# MCXN947_cm33_core0 register map
Vendor: nxp.com; File version: 1.0
CPU: CM33 r2p0, little endian, MPU, FPU, VTOR, 3 interrupt priority bits
Registers are 32-bit, read-write, reset 0x0 unless marked. A register's access mark holds for its fields unless they carry their own. Offsets are from the block's base; [hi:lo] are bit positions; lines under a group give offsets from that group; {n}, {i} and the like mark numbered series; 'fields as' and 'values as' point back to an identical list.

## CAN0 — CAN
Base 0x400D4000
Same registers: CAN1 0x400D8000
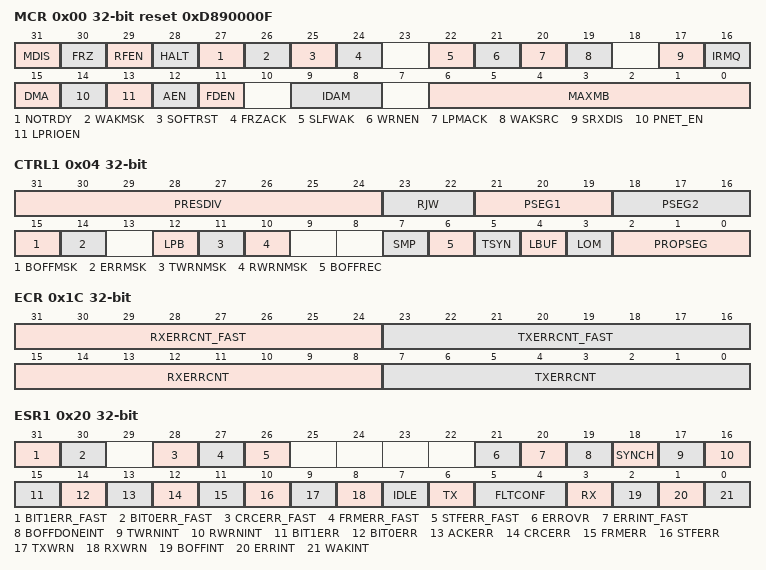
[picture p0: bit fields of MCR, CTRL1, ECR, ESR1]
0x00 MCR reset 0xD890000F — Module Configuration Register
  [31] MDIS — Module Disable
    0=flexcan_enabled (Enable the FlexCAN module.); 1=flexcan_disabled (Disable the FlexCAN module.)
  [30] FRZ — Freeze Enable
    0=freeze_mode_disabled (Not enabled to enter Freeze mode.); 1=freeze_mode_enabled (Enabled to enter Freeze mode.)
  [29] RFEN — Legacy Rx FIFO Enable
    0=id1 (Legacy Rx FIFO not enabled.); 1=id3 (Legacy Rx FIFO enabled.)
  [28] HALT — Halt FlexCAN
    0=HALT_disable (No Freeze mode request.); 1=HALT_enable (Enters Freeze mode if the FRZ bit is asserted.)
  [27] NOTRDY ro — FlexCAN Not Ready
    0=id1 (FlexCAN module is either in Normal mode, Listen-Only mode, or Loop-Back mode.); 1=id4 (FlexCAN module is either in Disable mode, Stop mode, or Freeze mode.)
  [26] WAKMSK — Wake Up Interrupt Mask
    0=wakeup_interrupt_disabled (Wake Up interrupt is disabled.); 1=wakeup_interrupt_enabled (Wake Up interrupt is enabled.)
  [25] SOFTRST — Soft Reset
    0=SOFTRST_no_reset_request (No reset request.); 1=SOFTRST_reset_registers (Resets the registers affected by soft reset.)
  [24] FRZACK ro — Freeze Mode Acknowledge
    0=freeze_mode_no (FlexCAN not in Freeze mode, prescaler running.); 1=freeze_mode_yes (FlexCAN in Freeze mode, prescaler stopped.)
  [22] SLFWAK — Self Wake Up
    0=self_wakeup_disabled (FlexCAN Self Wake Up feature is disabled.); 1=self_wakeup_enabled (FlexCAN Self Wake Up feature is enabled.)
  [21] WRNEN — Warning Interrupt Enable
    0=TWRNINT_RWRNINT_inactive (TWRNINT and RWRNINT bits are zero, independent of the values in the error counters.); 1=TWRNINT_RWRNINT_active (TWRNINT and RWRNINT bits are set when the respective error counter transitions from less than 96 to greater than or equal to 96.)
  [20] LPMACK ro — Low-Power Mode Acknowledge
    0=low_power_no (FlexCAN is not in a low-power mode.); 1=low_power_yes (FlexCAN is in a low-power mode.)
  [19] WAKSRC — Wake Up Source
    0=unfiltered_rx_input (FlexCAN uses the unfiltered Rx input to detect recessive to dominant edges on the CAN bus.); 1=filtered_rx_input (FlexCAN uses the filtered Rx input to detect recessive to dominant edges on the CAN bus.)
  [17] SRXDIS — Self Reception Disable
    0=self_reception_enabled; 1=self_reception_disabled
  [16] IRMQ — Individual Rx Masking And Queue Enable
    0=individual_rx_masking_disabled (Individual Rx masking and queue feature are disabled. For backward compatibility with legacy applications, the reading of C/S word locks the MB even if it is EMPTY.); 1=individual_rx_masking_enabled (Individual Rx masking and queue feature are enabled.)
  [15] DMA — DMA Enable
    0=id1 (DMA feature for Legacy RX FIFO or Enhanced Rx FIFO disabled.); 1=id3 (DMA feature for Legacy RX FIFO or Enhanced Rx FIFO enabled.)
  [14] PNET_EN — Pretended Networking Enable
    0=PN_disabled (Pretended Networking mode is disabled.); 1=PN_enabled (Pretended Networking mode is enabled.)
  [13] LPRIOEN — Local Priority Enable
    0=local_priority_disabled; 1=local_priority_enabled
  [12] AEN — Abort Enable
    0=abort_disabled; 1=abort_enabled
  [11] FDEN — CAN FD operation enable
    0=CAN_FD_disabled (CAN FD is disabled. FlexCAN is able to receive and transmit messages in CAN 2.0 format.); 1=CAN_FD_enabled (CAN FD is enabled. FlexCAN is able to receive and transmit messages in both CAN FD and CAN 2.0 formats.)
  [9:8] IDAM — ID Acceptance Mode
    0=one_full_ID (Format A: One full ID (standard and extended) per ID filter table element.); 1=two_full_ID (Format B: Two full standard IDs or two partial 14-bit (standard and extended) IDs per ID filter table element.); 2=four_partial_ID (Format C: Four partial 8-bit standard IDs per ID filter table element.); 3=all_frames_rejected (Format D: All frames rejected.)
  [6:0] MAXMB — Number Of The Last Message Buffer
0x04 CTRL1 — Control 1 Register
  [31:24] PRESDIV — Prescaler Division Factor
  [23:22] RJW — Resync Jump Width
  [21:19] PSEG1 — Phase Segment 1
  [18:16] PSEG2 — Phase Segment 2
  [15] BOFFMSK — Bus Off Interrupt Mask
    0=bus_off_int_disabled (Bus Off interrupt disabled.); 1=bus_off_int_enabled (Bus Off interrupt enabled.)
  [14] ERRMSK — Error Interrupt Mask
    0=error_int_disabled (Error interrupt disabled.); 1=error_int_enabled (Error interrupt enabled.)
  [12] LPB — Loop Back Mode
    0=loopback_disabled; 1=loopback_enabled
  [11] TWRNMSK — Tx Warning Interrupt Mask
    0=tx_warning_int_disabled (Tx Warning interrupt disabled.); 1=tx_warning_int_enabled (Tx Warning interrupt enabled.)
  [10] RWRNMSK — Rx Warning Interrupt Mask
    0=rx_warning_int_disabled (Rx Warning interrupt disabled.); 1=rx_warning_int_enabled (Rx Warning interrupt enabled.)
  [7] SMP — CAN Bit Sampling
    0=one_sample (Just one sample is used to determine the bit value.); 1=Three samples are used to determine the value of the received bit: the regular one (sample point) and two preceding samples; a majority rule is used
  [6] BOFFREC — Bus Off Recovery
    0=auto_recover_enabled (Automatic recovering from Bus Off state enabled.); 1=auto_recover_disabled (Automatic recovering from Bus Off state disabled.)
  [5] TSYN — Timer Sync
    0=timer_sync_disabled (Timer sync feature disabled); 1=timer_sync_enabled (Timer sync feature enabled)
  [4] LBUF — Lowest Buffer Transmitted First
    0=highest_buffer_first (Buffer with highest priority is transmitted first.); 1=lowest_buffer_first (Lowest number buffer is transmitted first.)
  [3] LOM — Listen-Only Mode
    0=listen_only_mode_disabled (Listen-Only mode is deactivated.); 1=listen_only_mode_enabled (FlexCAN module operates in Listen-Only mode.)
  [2:0] PROPSEG — Propagation Segment
0x08 TIMER — Free Running Timer
  [15:0] TIMER — Timer Value
0x10 RXMGMASK reset not defined — Rx Mailboxes Global Mask Register
  [31:0] MG — Rx Mailboxes Global Mask Bits
0x14 RX14MASK reset not defined
  [31:0] RX14M — Rx Buffer 14 Mask Bits
0x18 RX15MASK reset not defined
  [31:0] RX15M — Rx Buffer 15 Mask Bits
0x1C ECR — Error Counter
  [31:24] RXERRCNT_FAST — Receive Error Counter for fast bits
  [23:16] TXERRCNT_FAST — Transmit Error Counter for fast bits
  [15:8] RXERRCNT — Receive Error Counter
  [7:0] TXERRCNT — Transmit Error Counter
0x20 ESR1 — Error and Status 1 Register
  [31] BIT1ERR_FAST ro — Bit1 Error in the Data Phase of CAN FD frames with the BRS bit set
    0=bit1_error_no (No such occurrence.); 1=bit1_error_yes (At least one bit sent as recessive is received as dominant.)
  [30] BIT0ERR_FAST ro — Bit0 Error in the Data Phase of CAN FD frames with the BRS bit set
    0=bit0_error_no (No such occurrence.); 1=bit0_error_yes (At least one bit sent as dominant is received as recessive.)
  [28] CRCERR_FAST ro — Cyclic Redundancy Check Error in the CRC field of CAN FD frames with the BRS bit set
    0=CRC_error_no (No such occurrence.); 1=CRC_error_yes (A CRC error occurred since last read of this register.)
  [27] FRMERR_FAST ro — Form Error in the Data Phase of CAN FD frames with the BRS bit set
    0=form_error_no (No such occurrence.); 1=form_error_yes (A form error occurred since last read of this register.)
  [26] STFERR_FAST ro — Stuffing Error in the Data Phase of CAN FD frames with the BRS bit set
    0=stuffing_error_no (No such occurrence.); 1=stuffing_error_yes (A stuffing error occurred since last read of this register.)
  [21] ERROVR write-1-clears — Error Overrun
    0=overrun_not_occurred (Overrun has not occurred.); 1=overrun_occurred (Overrun has occurred.)
  [20] ERRINT_FAST write-1-clears — Error interrupt for errors detected in Data Phase of CAN FD frames with BRS bit set
    0=errors_data_phase_no (No such occurrence.); 1=errors_data_phase_yes (Indicates setting of any error bit detected in the data phase of CAN FD frames with the BRS bit set.)
  [19] BOFFDONEINT write-1-clears — Bus Off Done Interrupt
    0=bus_off_not_done (No such occurrence.); 1=bus_off_done (FlexCAN module has completed Bus Off process.)
  [18] SYNCH ro — CAN Synchronization Status
    0=CAN_bus_sync_no (FlexCAN is not synchronized to the CAN bus.); 1=CAN_bus_sync_yes (FlexCAN is synchronized to the CAN bus.)
  [17] TWRNINT write-1-clears — Tx Warning Interrupt Flag
    0=Tx_warning_int_no (No such occurrence.); 1=Tx_warning_int_yes (The Tx error counter transitioned from less than 96 to greater than or equal to 96.)
  [16] RWRNINT write-1-clears — Rx Warning Interrupt Flag
    0=Rx_warning_int_no (No such occurrence.); 1=Rx_warning_int_yes (The Rx error counter transitioned from less than 96 to greater than or equal to 96.)
  [15] BIT1ERR ro — Bit1 Error
    values as BIT1ERR_FAST
  [14] BIT0ERR ro — Bit0 Error
    values as BIT0ERR_FAST
  [13] ACKERR ro — Acknowledge Error
    0=ACK_error_no (No such occurrence.); 1=ACK_error_yes (An ACK error occurred since last read of this register.)
  [12] CRCERR ro — Cyclic Redundancy Check Error
    values as CRCERR_FAST
  [11] FRMERR ro — Form Error
    0=form_error_no (No such occurrence.); 1=form_error_yes (A Form Error occurred since last read of this register.)
  [10] STFERR ro — Stuffing Error
    values as STFERR_FAST
  [9] TXWRN ro — TX Error Warning
    0=TXERRCNT_LT_96 (No such occurrence.); 1=TXERRCNT_GTE_96 (TXERRCNT is greater than or equal to 96.)
  [8] RXWRN ro — Rx Error Warning
    0=RXERRCNT_LT_96 (No such occurrence.); 1=RXERRCNT_GTE_96 (RXERRCNT is greater than or equal to 96.)
  [7] IDLE ro
    0=can_bus_not_idle (No such occurrence.); 1=can_bus_idle (CAN bus is now IDLE.)
  [6] TX ro — FlexCAN In Transmission
    0=transmit_message_no (FlexCAN is not transmitting a message.); 1=transmit_message_yes (FlexCAN is transmitting a message.)
  [5:4] FLTCONF ro — Fault Confinement State
    0=error_active; 1=error_passive; 0b1x=bus_off
  [3] RX ro — FlexCAN In Reception
    0=DISABLE (FlexCAN is not receiving a message.); 1=ENABLE (FlexCAN is receiving a message.)
  [2] BOFFINT write-1-clears — Bus Off Interrupt
    0=DISABLE (No such occurrence.); 1=ENABLE (FlexCAN module entered Bus Off state.)
  [1] ERRINT write-1-clears — Error Interrupt
    0=DISABLE (No such occurrence.); 1=ENABLE (Indicates setting of any error bit in the Error and Status register.)
  [0] WAKINT write-1-clears — Wake-Up Interrupt
    0=DISABLE (No such occurrence.); 1=ENABLE (Indicates a recessive to dominant transition was received on the CAN bus.)
0x28 IMASK1 — Interrupt Masks 1 Register
  [31:0] BUF31TO0M — Buffer MBi Mask
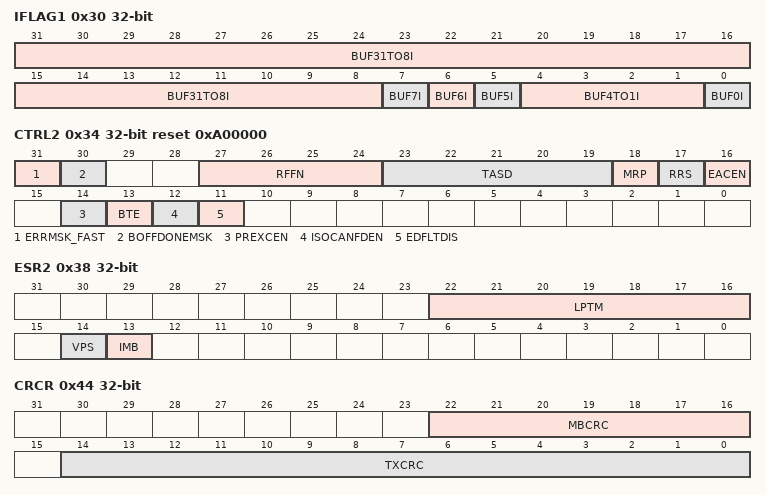
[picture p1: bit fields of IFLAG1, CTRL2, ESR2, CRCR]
0x30 IFLAG1 write-1-clears — Interrupt Flags 1 Register
  [31:8] BUF31TO8I write-1-clears — Buffer MBi Interrupt
  [7] BUF7I write-1-clears — Buffer MB7 Interrupt Or Legacy Rx FIFO Overflow
    0=id1 (No occurrence of MB7 completing transmission/reception when MCR[RFEN]=0, or of Legacy Rx FIFO overflow when MCR[RFEN]=1); 1=id3 (MB7 completed transmission/reception when MCR[RFEN]=0, or Legacy Rx FIFO overflow when MCR[RFEN]=1)
  [6] BUF6I write-1-clears — Buffer MB6 Interrupt Or Legacy Rx FIFO Warning
    0=id1 (No occurrence of MB6 completing transmission/reception when MCR[RFEN]=0, or of Legacy Rx FIFO almost full when MCR[RFEN]=1); 1=id3 (MB6 completed transmission/reception when MCR[RFEN]=0, or Legacy Rx FIFO almost full when MCR[RFEN]=1)
  [5] BUF5I write-1-clears — Buffer MB5 Interrupt Or Frames available in Legacy Rx FIFO
    0=id1 (No occurrence of MB5 completing transmission/reception when MCR[RFEN]=0, or of frame(s) available in the Legacy FIFO, when MCR[RFEN]=1); 1=id3 (MB5 completed transmission/reception when MCR[RFEN]=0, or frame(s) available in the Legacy Rx FIFO when MCR[RFEN]=1. It generates a DMA request in case of MCR[RFEN] and MCR[DMA] are enabled.)
  [4:1] BUF4TO1I write-1-clears — Buffer MBi Interrupt Or Reserved
  [0] BUF0I write-1-clears — Buffer MB0 Interrupt Or Clear Legacy FIFO bit
    0=buffer_Tx_Rx_not_complete (The corresponding buffer has no occurrence of successfully completed transmission or reception when MCR[RFEN]=0.); 1=buffer_Tx_Rx_complete (The corresponding buffer has successfully completed transmission or reception when MCR[RFEN]=0.)
0x34 CTRL2 reset 0xA00000 — Control 2 Register
  [31] ERRMSK_FAST — Error Interrupt Mask for errors detected in the data phase of fast CAN FD frames
    0=DISABLE (ERRINT_FAST error interrupt disabled.); 1=ENABLE (ERRINT_FAST error interrupt enabled.)
  [30] BOFFDONEMSK — Bus Off Done Interrupt Mask
    0=DISABLE (Bus off done interrupt disabled.); 1=ENABLE (Bus off done interrupt enabled.)
  [27:24] RFFN — Number Of Legacy Rx FIFO Filters
  [23:19] TASD — Tx Arbitration Start Delay
  [18] MRP — Mailboxes Reception Priority
    0=id1 (Matching starts from Legacy Rx FIFO or Enhanced Rx FIFO and continues on mailboxes.); 1=id3 (Matching starts from mailboxes and continues on Legacy Rx FIFO or Enhanced Rx FIFO.)
  [17] RRS — Remote Request Storing
    0=remote_response_frame_not_generated (Remote response frame is generated.); 1=remote_response_frame_generated (Remote request frame is stored.)
  [16] EACEN — Entire Frame Arbitration Field Comparison Enable For Rx Mailboxes
    0=RTR_compare_no (Rx mailbox filter's IDE bit is always compared and RTR is never compared despite mask bits.); 1=RTR_compare_yes (Enables the comparison of both Rx mailbox filter's IDE and RTR bit with their corresponding bits within the incoming frame. Mask bits do apply.)
  [14] PREXCEN — Protocol Exception Enable
    0=DISABLE (Protocol exception is disabled.); 1=ENABLE (Protocol exception is enabled.)
  [13] BTE — Bit Timing Expansion enable
    0=DISABLE (CAN Bit timing expansion is disabled.); 1=ENABLE (CAN bit timing expansion is enabled.)
  [12] ISOCANFDEN — ISO CAN FD Enable
    0=non_ISO (FlexCAN operates using the non-ISO CAN FD protocol.); 1=ISO (FlexCAN operates using the ISO CAN FD protocol (ISO 11898-1:2015).)
  [11] EDFLTDIS — Edge Filter Disable
    0=ENABLE (Edge filter is enabled); 1=DISABLE (Edge filter is disabled)
0x38 ESR2 ro — Error and Status 2 Register
  [22:16] LPTM — Lowest Priority Tx Mailbox
  [14] VPS — Valid Priority Status
    0=invalid (Contents of IMB and LPTM are invalid.); 1=valid (Contents of IMB and LPTM are valid.)
  [13] IMB — Inactive Mailbox
    0=inactive_mailbox_no (If ESR2[VPS] is asserted, the ESR2[LPTM] is not an inactive mailbox.); 1=inactive_mailbox_yes (If ESR2[VPS] is asserted, there is at least one inactive mailbox. LPTM content is the number of the first one.)
0x44 CRCR ro — CRC Register
  [22:16] MBCRC — CRC Mailbox
  [14:0] TXCRC — Transmitted CRC value
0x48 RXFGMASK reset not defined — Legacy Rx FIFO Global Mask Register
  [31:0] FGM — Legacy Rx FIFO Global Mask Bits
0x4C RXFIR ro reset not defined — Legacy Rx FIFO Information Register
  [8:0] IDHIT — Identifier Acceptance Filter Hit Indicator
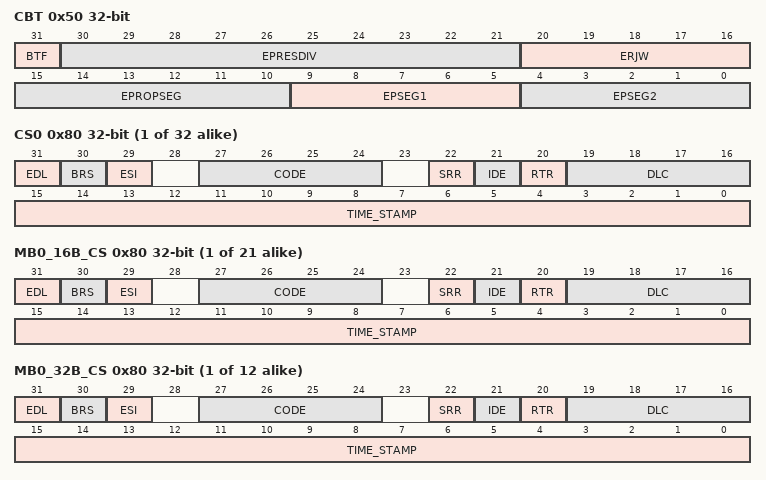
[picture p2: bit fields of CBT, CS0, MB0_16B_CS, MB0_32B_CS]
0x50 CBT — CAN Bit Timing Register
  [31] BTF — Bit Timing Format Enable
    0=DISABLE (Extended bit time definitions disabled.); 1=ENABLE (Extended bit time definitions enabled.)
  [30:21] EPRESDIV — Extended Prescaler Division Factor
  [20:16] ERJW — Extended Resync Jump Width
  [15:10] EPROPSEG — Extended Propagation Segment
  [9:5] EPSEG1 — Extended Phase Segment 1
  [4:0] EPSEG2 — Extended Phase Segment 2
{0x80+0x10*i} CS{i} (MB_SIZE view) (i=0..31) — Message Buffer {i} CS Register
  [31] EDL — Extended Data Length. This bit distinguishes between CAN format and CAN FD format frames. The EDL bit must not be set for Message Buffers configured to RANSWER with code field 0b1010.
  [30] BRS — Bit Rate Switch. This bit defines whether the bit rate is switched inside a CAN FD format frame.
  [29] ESI — Error State Indicator. This bit indicates if the transmitting node is error active or error passive.
  [27:24] CODE — Message Buffer Code. This 4-bit field can be accessed (read or write) by the CPU and by the FlexCAN module itself, as part of the message buffer matching and arbitration process.
  [22] SRR — Substitute Remote Request. Contains a fixed recessive bit.
  [21] IDE — ID Extended. One/zero for extended/standard format frame.
  [20] RTR — Remote Transmission Request. One/zero for remote/data frame.
  [19:16] DLC — Length of the data to be stored/transmitted.
  [15:0] TIME_STAMP — Free-Running Counter Time stamp. This 16-bit field is a copy of the Free-Running Timer, captured for Tx and Rx frames at the time when the beginning of the Identifier field appears on the CAN bus.
{0x80+0x18*i} MB{i}_16B_CS (MB_SIZE view) (i=0..20) — Message Buffer {i} CS Register
  fields as CS0
{0x80+0x28*i} MB{i}_32B_CS (MB_SIZE view) (i=0..11) — Message Buffer {i} CS Register
  fields as CS0
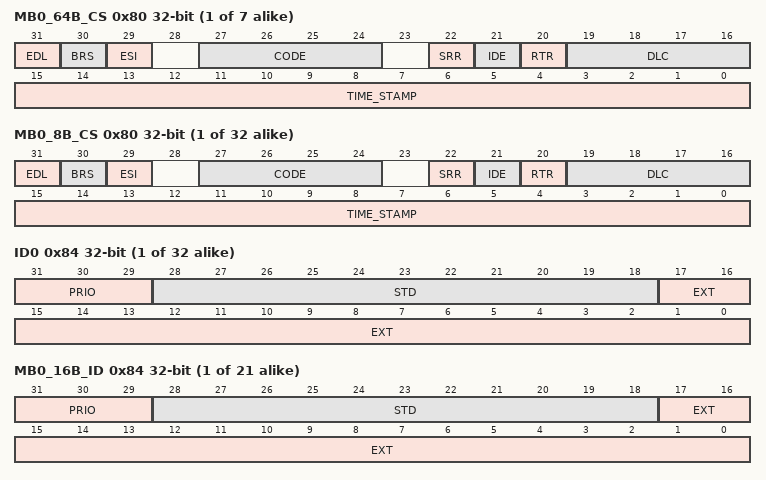
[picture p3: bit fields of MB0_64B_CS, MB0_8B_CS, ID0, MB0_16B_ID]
{0x80+0x48*i} MB{i}_64B_CS (MB_SIZE view) (i=0..6) — Message Buffer {i} CS Register
  fields as CS0
{0x80+0x10*i} MB{i}_8B_CS (MB_SIZE view) (i=0..31) — Message Buffer {i} CS Register
  fields as CS0
{0x84+0x10*i} ID{i} (MB_SIZE view) (i=0..31) — Message Buffer {i} ID Register
  [31:29] PRIO — Local priority. This 3-bit fieldis only used when LPRIO_EN bit is set in MCR and it only makes sense for Tx buffers. These bits are not transmitted. They are appended to the regular ID to define the transmission priority.
  [28:18] STD — Contains standard/extended (HIGH word) identifier of message buffer.
  [17:0] EXT — Contains extended (LOW word) identifier of message buffer.
{0x84+0x18*i} MB{i}_16B_ID (MB_SIZE view) (i=0..20) — Message Buffer {i} ID Register
  fields as ID0
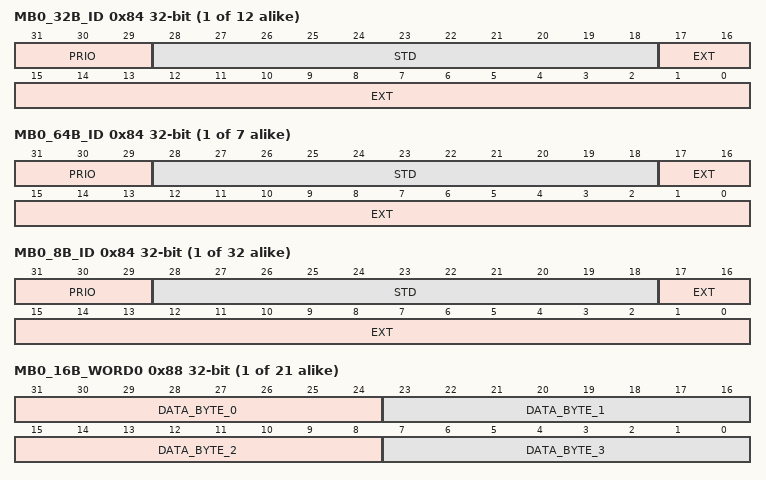
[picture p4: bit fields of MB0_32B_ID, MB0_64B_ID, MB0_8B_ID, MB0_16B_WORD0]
{0x84+0x28*i} MB{i}_32B_ID (MB_SIZE view) (i=0..11) — Message Buffer {i} ID Register
  fields as ID0
{0x84+0x48*i} MB{i}_64B_ID (MB_SIZE view) (i=0..6) — Message Buffer {i} ID Register
  fields as ID0
{0x84+0x10*i} MB{i}_8B_ID (MB_SIZE view) (i=0..31) — Message Buffer {i} ID Register
  fields as ID0
{0x88+0x18*i} MB{i}_16B_WORD0 (MB_SIZE view) (i=0..20) — Message Buffer {i} WORD_16B Register
  [31:24] DATA_BYTE_0 — Data byte 3 of Rx/Tx frame.
  [23:16] DATA_BYTE_1 — Data byte 2 of Rx/Tx frame.
  [15:8] DATA_BYTE_2 — Data byte 1 of Rx/Tx frame.
  [7:0] DATA_BYTE_3 — Data byte 0 of Rx/Tx frame.
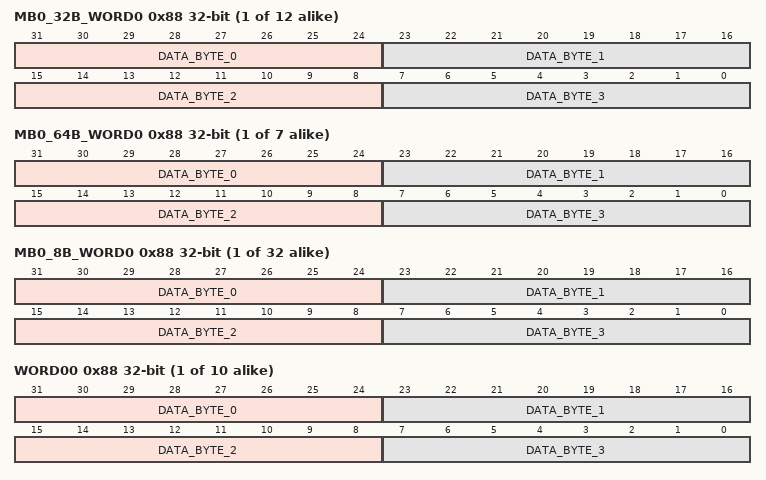
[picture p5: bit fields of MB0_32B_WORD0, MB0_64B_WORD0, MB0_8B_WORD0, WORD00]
{0x88+0x28*i} MB{i}_32B_WORD0 (MB_SIZE view) (i=0..11) — Message Buffer {i} WORD_32B Register
  fields as MB0_16B_WORD0
{0x88+0x48*i} MB{i}_64B_WORD0 (MB_SIZE view) (i=0..6) — Message Buffer {i} WORD_64B Register
  fields as MB0_16B_WORD0
{0x88+0x10*i} MB{i}_8B_WORD0 (MB_SIZE view) (i=0..31) — Message Buffer {i} WORD_8B Register
  fields as MB0_16B_WORD0
{0x88+0x10*i} WORD{i:02} (MB_SIZE view) (i=0..9) — Message Buffer {i} WORD0 Register
  fields as MB0_16B_WORD0
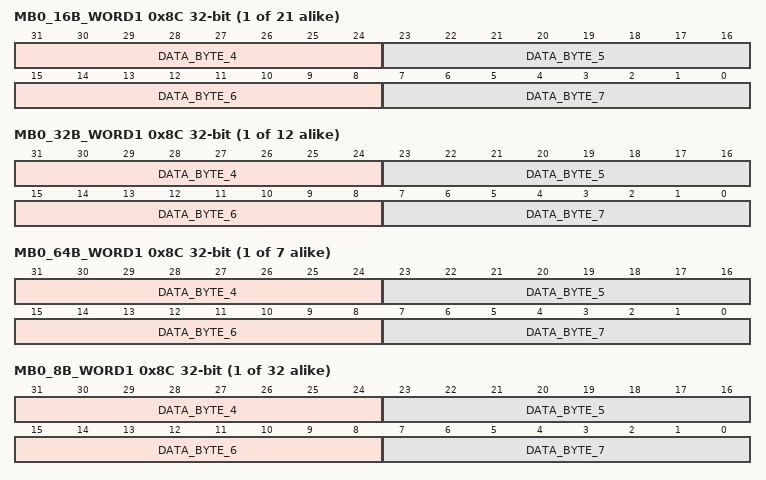
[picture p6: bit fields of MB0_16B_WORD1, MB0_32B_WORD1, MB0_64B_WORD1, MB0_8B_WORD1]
{0x8C+0x18*i} MB{i}_16B_WORD1 (MB_SIZE view) (i=0..20) — Message Buffer {i} WORD_16B Register
  [31:24] DATA_BYTE_4 — Data byte 3 of Rx/Tx frame.
  [23:16] DATA_BYTE_5 — Data byte 2 of Rx/Tx frame.
  [15:8] DATA_BYTE_6 — Data byte 1 of Rx/Tx frame.
  [7:0] DATA_BYTE_7 — Data byte 0 of Rx/Tx frame.
{0x8C+0x28*i} MB{i}_32B_WORD1 (MB_SIZE view) (i=0..11) — Message Buffer {i} WORD_32B Register
  fields as MB0_16B_WORD1
{0x8C+0x48*i} MB{i}_64B_WORD1 (MB_SIZE view) (i=0..6) — Message Buffer {i} WORD_64B Register
  fields as MB0_16B_WORD1
{0x8C+0x10*i} MB{i}_8B_WORD1 (MB_SIZE view) (i=0..31) — Message Buffer {i} WORD_8B Register
  fields as MB0_16B_WORD1
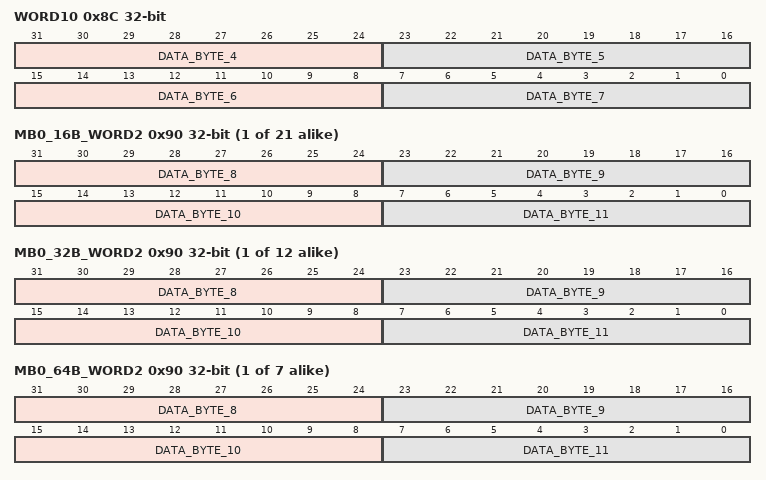
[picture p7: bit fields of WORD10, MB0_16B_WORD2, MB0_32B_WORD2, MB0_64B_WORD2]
0x8C WORD10 (MB_SIZE view) — Message Buffer 0 WORD1 Register
  fields as MB0_16B_WORD1
{0x90+0x18*i} MB{i}_16B_WORD2 (MB_SIZE view) (i=0..20) — Message Buffer {i} WORD_16B Register
  [31:24] DATA_BYTE_8 — Data byte 3 of Rx/Tx frame.
  [23:16] DATA_BYTE_9 — Data byte 2 of Rx/Tx frame.
  [15:8] DATA_BYTE_10 — Data byte 1 of Rx/Tx frame.
  [7:0] DATA_BYTE_11 — Data byte 0 of Rx/Tx frame.
{0x90+0x28*i} MB{i}_32B_WORD2 (MB_SIZE view) (i=0..11) — Message Buffer {i} WORD_32B Register
  fields as MB0_16B_WORD2
{0x90+0x48*i} MB{i}_64B_WORD2 (MB_SIZE view) (i=0..6) — Message Buffer {i} WORD_64B Register
  fields as MB0_16B_WORD2
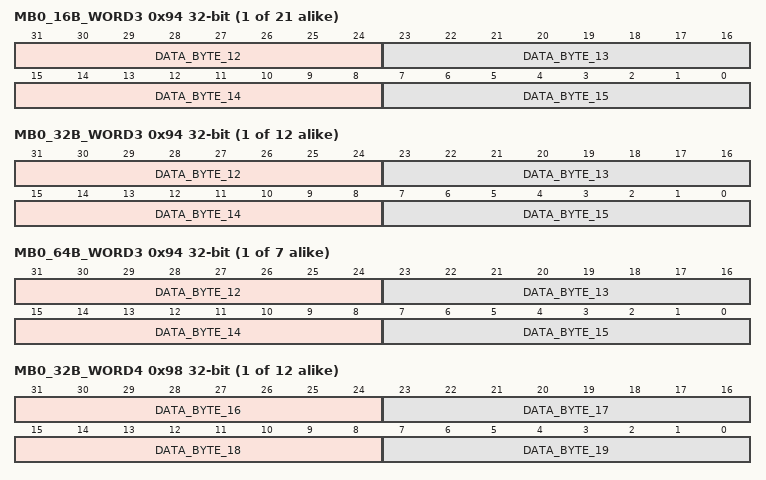
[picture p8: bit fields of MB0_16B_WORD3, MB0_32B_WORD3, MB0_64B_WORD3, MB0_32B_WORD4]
{0x94+0x18*i} MB{i}_16B_WORD3 (MB_SIZE view) (i=0..20) — Message Buffer {i} WORD_16B Register
  [31:24] DATA_BYTE_12 — Data byte 3 of Rx/Tx frame.
  [23:16] DATA_BYTE_13 — Data byte 2 of Rx/Tx frame.
  [15:8] DATA_BYTE_14 — Data byte 1 of Rx/Tx frame.
  [7:0] DATA_BYTE_15 — Data byte 0 of Rx/Tx frame.
{0x94+0x28*i} MB{i}_32B_WORD3 (MB_SIZE view) (i=0..11) — Message Buffer {i} WORD_32B Register
  fields as MB0_16B_WORD3
{0x94+0x48*i} MB{i}_64B_WORD3 (MB_SIZE view) (i=0..6) — Message Buffer {i} WORD_64B Register
  fields as MB0_16B_WORD3
{0x98+0x28*i} MB{i}_32B_WORD4 (MB_SIZE view) (i=0..11) — Message Buffer {i} WORD_32B Register
  [31:24] DATA_BYTE_16 — Data byte 3 of Rx/Tx frame.
  [23:16] DATA_BYTE_17 — Data byte 2 of Rx/Tx frame.
  [15:8] DATA_BYTE_18 — Data byte 1 of Rx/Tx frame.
  [7:0] DATA_BYTE_19 — Data byte 0 of Rx/Tx frame.
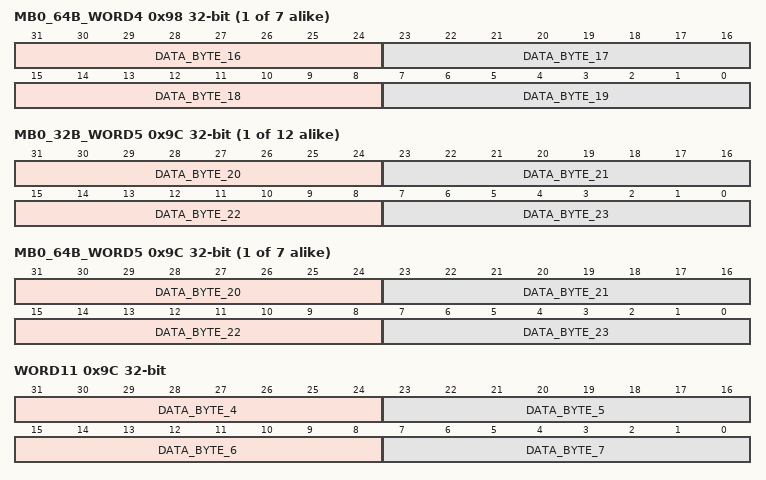
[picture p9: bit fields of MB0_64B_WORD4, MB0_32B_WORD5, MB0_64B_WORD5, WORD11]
{0x98+0x48*i} MB{i}_64B_WORD4 (MB_SIZE view) (i=0..6) — Message Buffer {i} WORD_64B Register
  fields as MB0_32B_WORD4
{0x9C+0x28*i} MB{i}_32B_WORD5 (MB_SIZE view) (i=0..11) — Message Buffer {i} WORD_32B Register
  [31:24] DATA_BYTE_20 — Data byte 3 of Rx/Tx frame.
  [23:16] DATA_BYTE_21 — Data byte 2 of Rx/Tx frame.
  [15:8] DATA_BYTE_22 — Data byte 1 of Rx/Tx frame.
  [7:0] DATA_BYTE_23 — Data byte 0 of Rx/Tx frame.
{0x9C+0x48*i} MB{i}_64B_WORD5 (MB_SIZE view) (i=0..6) — Message Buffer {i} WORD_64B Register
  fields as MB0_32B_WORD5
0x9C WORD11 (MB_SIZE view) — Message Buffer 1 WORD1 Register
  fields as MB0_16B_WORD1
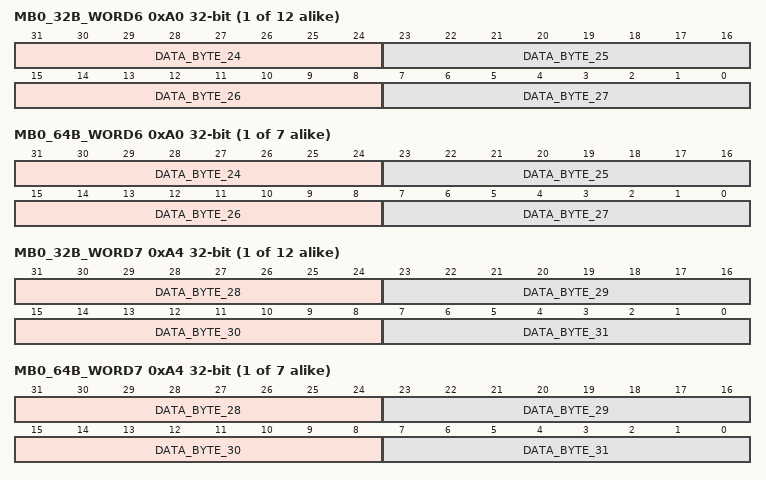
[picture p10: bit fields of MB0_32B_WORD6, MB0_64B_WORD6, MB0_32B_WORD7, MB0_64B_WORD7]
{0xA0+0x28*i} MB{i}_32B_WORD6 (MB_SIZE view) (i=0..11) — Message Buffer {i} WORD_32B Register
  [31:24] DATA_BYTE_24 — Data byte 3 of Rx/Tx frame.
  [23:16] DATA_BYTE_25 — Data byte 2 of Rx/Tx frame.
  [15:8] DATA_BYTE_26 — Data byte 1 of Rx/Tx frame.
  [7:0] DATA_BYTE_27 — Data byte 0 of Rx/Tx frame.
{0xA0+0x48*i} MB{i}_64B_WORD6 (MB_SIZE view) (i=0..6) — Message Buffer {i} WORD_64B Register
  fields as MB0_32B_WORD6
{0xA4+0x28*i} MB{i}_32B_WORD7 (MB_SIZE view) (i=0..11) — Message Buffer {i} WORD_32B Register
  [31:24] DATA_BYTE_28 — Data byte 3 of Rx/Tx frame.
  [23:16] DATA_BYTE_29 — Data byte 2 of Rx/Tx frame.
  [15:8] DATA_BYTE_30 — Data byte 1 of Rx/Tx frame.
  [7:0] DATA_BYTE_31 — Data byte 0 of Rx/Tx frame.
{0xA4+0x48*i} MB{i}_64B_WORD7 (MB_SIZE view) (i=0..6) — Message Buffer {i} WORD_64B Register
  fields as MB0_32B_WORD7
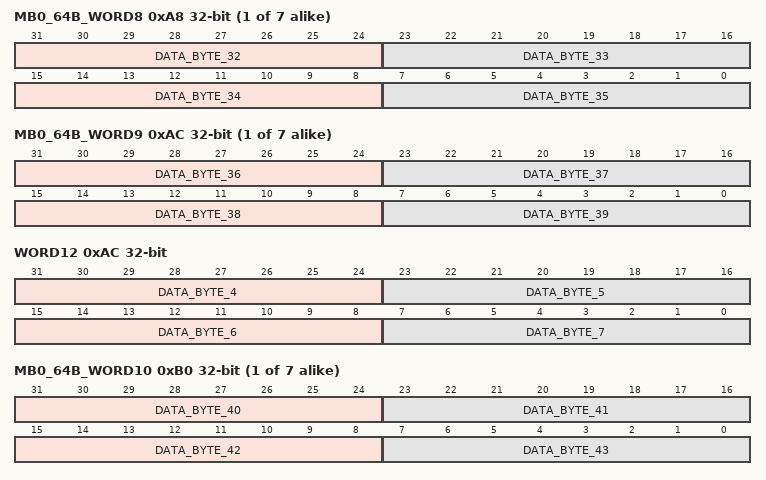
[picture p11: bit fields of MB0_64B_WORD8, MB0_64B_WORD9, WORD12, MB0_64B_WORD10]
{0xA8+0x48*i} MB{i}_64B_WORD8 (MB_SIZE view) (i=0..6) — Message Buffer {i} WORD_64B Register
  [31:24] DATA_BYTE_32 — Data byte 3 of Rx/Tx frame.
  [23:16] DATA_BYTE_33 — Data byte 2 of Rx/Tx frame.
  [15:8] DATA_BYTE_34 — Data byte 1 of Rx/Tx frame.
  [7:0] DATA_BYTE_35 — Data byte 0 of Rx/Tx frame.
{0xAC+0x48*i} MB{i}_64B_WORD9 (MB_SIZE view) (i=0..6) — Message Buffer {i} WORD_64B Register
  [31:24] DATA_BYTE_36 — Data byte 3 of Rx/Tx frame.
  [23:16] DATA_BYTE_37 — Data byte 2 of Rx/Tx frame.
  [15:8] DATA_BYTE_38 — Data byte 1 of Rx/Tx frame.
  [7:0] DATA_BYTE_39 — Data byte 0 of Rx/Tx frame.
0xAC WORD12 (MB_SIZE view) — Message Buffer 2 WORD1 Register
  fields as MB0_16B_WORD1
{0xB0+0x48*i} MB{i}_64B_WORD10 (MB_SIZE view) (i=0..6) — Message Buffer {i} WORD_64B Register
  [31:24] DATA_BYTE_40 — Data byte 3 of Rx/Tx frame.
  [23:16] DATA_BYTE_41 — Data byte 2 of Rx/Tx frame.
  [15:8] DATA_BYTE_42 — Data byte 1 of Rx/Tx frame.
  [7:0] DATA_BYTE_43 — Data byte 0 of Rx/Tx frame.
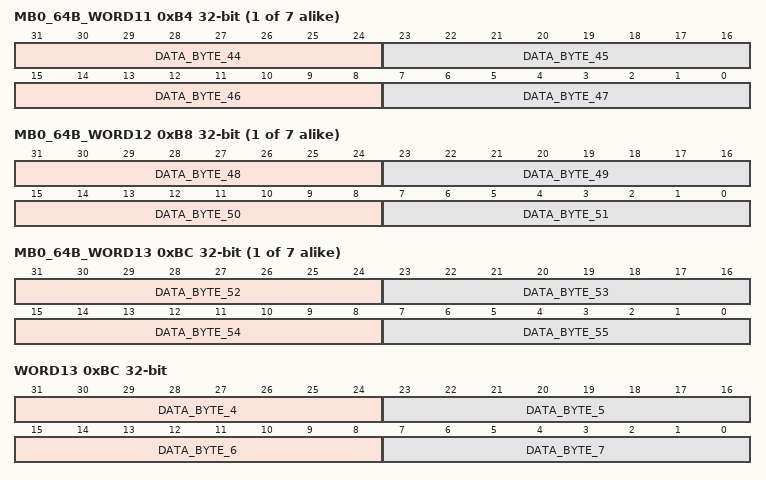
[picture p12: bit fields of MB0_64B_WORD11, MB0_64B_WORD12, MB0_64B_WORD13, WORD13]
{0xB4+0x48*i} MB{i}_64B_WORD11 (MB_SIZE view) (i=0..6) — Message Buffer {i} WORD_64B Register
  [31:24] DATA_BYTE_44 — Data byte 3 of Rx/Tx frame.
  [23:16] DATA_BYTE_45 — Data byte 2 of Rx/Tx frame.
  [15:8] DATA_BYTE_46 — Data byte 1 of Rx/Tx frame.
  [7:0] DATA_BYTE_47 — Data byte 0 of Rx/Tx frame.
{0xB8+0x48*i} MB{i}_64B_WORD12 (MB_SIZE view) (i=0..6) — Message Buffer {i} WORD_64B Register
  [31:24] DATA_BYTE_48 — Data byte 3 of Rx/Tx frame.
  [23:16] DATA_BYTE_49 — Data byte 2 of Rx/Tx frame.
  [15:8] DATA_BYTE_50 — Data byte 1 of Rx/Tx frame.
  [7:0] DATA_BYTE_51 — Data byte 0 of Rx/Tx frame.
{0xBC+0x48*i} MB{i}_64B_WORD13 (MB_SIZE view) (i=0..6) — Message Buffer {i} WORD_64B Register
  [31:24] DATA_BYTE_52 — Data byte 3 of Rx/Tx frame.
  [23:16] DATA_BYTE_53 — Data byte 2 of Rx/Tx frame.
  [15:8] DATA_BYTE_54 — Data byte 1 of Rx/Tx frame.
  [7:0] DATA_BYTE_55 — Data byte 0 of Rx/Tx frame.
0xBC WORD13 (MB_SIZE view) — Message Buffer 3 WORD1 Register
  fields as MB0_16B_WORD1
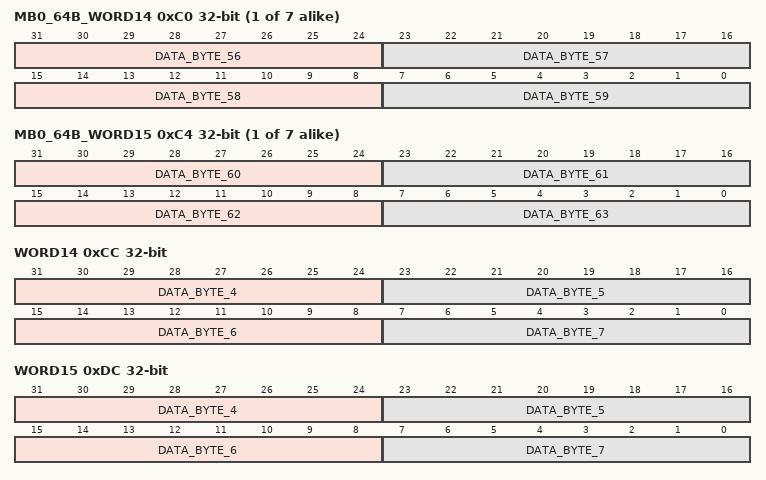
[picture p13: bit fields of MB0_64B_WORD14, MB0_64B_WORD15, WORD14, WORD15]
{0xC0+0x48*i} MB{i}_64B_WORD14 (MB_SIZE view) (i=0..6) — Message Buffer {i} WORD_64B Register
  [31:24] DATA_BYTE_56 — Data byte 3 of Rx/Tx frame.
  [23:16] DATA_BYTE_57 — Data byte 2 of Rx/Tx frame.
  [15:8] DATA_BYTE_58 — Data byte 1 of Rx/Tx frame.
  [7:0] DATA_BYTE_59 — Data byte 0 of Rx/Tx frame.
{0xC4+0x48*i} MB{i}_64B_WORD15 (MB_SIZE view) (i=0..6) — Message Buffer {i} WORD_64B Register
  [31:24] DATA_BYTE_60 — Data byte 3 of Rx/Tx frame.
  [23:16] DATA_BYTE_61 — Data byte 2 of Rx/Tx frame.
  [15:8] DATA_BYTE_62 — Data byte 1 of Rx/Tx frame.
  [7:0] DATA_BYTE_63 — Data byte 0 of Rx/Tx frame.
0xCC WORD14 (MB_SIZE view) — Message Buffer 4 WORD1 Register
  fields as MB0_16B_WORD1
0xDC WORD15 (MB_SIZE view) — Message Buffer 5 WORD1 Register
  fields as MB0_16B_WORD1
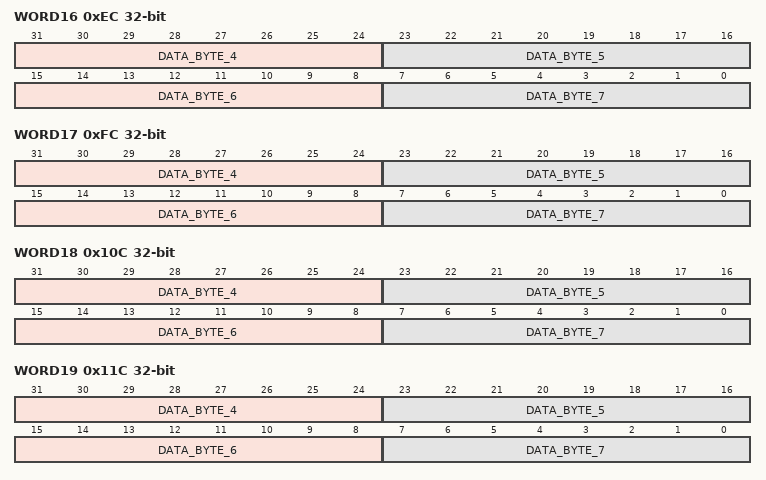
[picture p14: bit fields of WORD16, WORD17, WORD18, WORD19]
0xEC WORD16 (MB_SIZE view) — Message Buffer 6 WORD1 Register
  fields as MB0_16B_WORD1
0xFC WORD17 (MB_SIZE view) — Message Buffer 7 WORD1 Register
  fields as MB0_16B_WORD1
0x10C WORD18 (MB_SIZE view) — Message Buffer 8 WORD1 Register
  fields as MB0_16B_WORD1
0x11C WORD19 (MB_SIZE view) — Message Buffer 9 WORD1 Register
  fields as MB0_16B_WORD1
0x128 WORD010 (MB_SIZE view) — Message Buffer 10 WORD0 Register
  fields as MB0_16B_WORD0
0x12C WORD110 (MB_SIZE view) — Message Buffer 10 WORD1 Register
  fields as MB0_16B_WORD1
0x138 WORD011 (MB_SIZE view) — Message Buffer 11 WORD0 Register
  fields as MB0_16B_WORD0
0x13C WORD111 (MB_SIZE view) — Message Buffer 11 WORD1 Register
  fields as MB0_16B_WORD1
0x148 WORD012 (MB_SIZE view) — Message Buffer 12 WORD0 Register
  fields as MB0_16B_WORD0
0x14C WORD112 (MB_SIZE view) — Message Buffer 12 WORD1 Register
  fields as MB0_16B_WORD1
0x158 WORD013 (MB_SIZE view) — Message Buffer 13 WORD0 Register
  fields as MB0_16B_WORD0
0x15C WORD113 (MB_SIZE view) — Message Buffer 13 WORD1 Register
  fields as MB0_16B_WORD1
0x168 WORD014 (MB_SIZE view) — Message Buffer 14 WORD0 Register
  fields as MB0_16B_WORD0
0x16C WORD114 (MB_SIZE view) — Message Buffer 14 WORD1 Register
  fields as MB0_16B_WORD1
0x178 WORD015 (MB_SIZE view) — Message Buffer 15 WORD0 Register
  fields as MB0_16B_WORD0
0x17C WORD115 (MB_SIZE view) — Message Buffer 15 WORD1 Register
  fields as MB0_16B_WORD1
0x188 WORD016 (MB_SIZE view) — Message Buffer 16 WORD0 Register
  fields as MB0_16B_WORD0
0x18C WORD116 (MB_SIZE view) — Message Buffer 16 WORD1 Register
  fields as MB0_16B_WORD1
0x198 WORD017 (MB_SIZE view) — Message Buffer 17 WORD0 Register
  fields as MB0_16B_WORD0
0x19C WORD117 (MB_SIZE view) — Message Buffer 17 WORD1 Register
  fields as MB0_16B_WORD1
0x1A8 WORD018 (MB_SIZE view) — Message Buffer 18 WORD0 Register
  fields as MB0_16B_WORD0
0x1AC WORD118 (MB_SIZE view) — Message Buffer 18 WORD1 Register
  fields as MB0_16B_WORD1
{0x88+0x10*i} WORD{i:03} (MB_SIZE view) (i=19..31) — Message Buffer {i} WORD0 Register
  fields as MB0_16B_WORD0
0x1BC WORD119 (MB_SIZE view) — Message Buffer 19 WORD1 Register
  fields as MB0_16B_WORD1
0x1CC WORD120 (MB_SIZE view) — Message Buffer 20 WORD1 Register
  fields as MB0_16B_WORD1
0x1DC WORD121 (MB_SIZE view) — Message Buffer 21 WORD1 Register
  fields as MB0_16B_WORD1
0x1EC WORD122 (MB_SIZE view) — Message Buffer 22 WORD1 Register
  fields as MB0_16B_WORD1
0x1FC WORD123 (MB_SIZE view) — Message Buffer 23 WORD1 Register
  fields as MB0_16B_WORD1
0x20C WORD124 (MB_SIZE view) — Message Buffer 24 WORD1 Register
  fields as MB0_16B_WORD1
0x21C WORD125 (MB_SIZE view) — Message Buffer 25 WORD1 Register
  fields as MB0_16B_WORD1
0x22C WORD126 (MB_SIZE view) — Message Buffer 26 WORD1 Register
  fields as MB0_16B_WORD1
0x23C WORD127 (MB_SIZE view) — Message Buffer 27 WORD1 Register
  fields as MB0_16B_WORD1
0x24C WORD128 (MB_SIZE view) — Message Buffer 28 WORD1 Register
  fields as MB0_16B_WORD1
0x25C WORD129 (MB_SIZE view) — Message Buffer 29 WORD1 Register
  fields as MB0_16B_WORD1
0x26C WORD130 (MB_SIZE view) — Message Buffer 30 WORD1 Register
  fields as MB0_16B_WORD1
0x27C WORD131 (MB_SIZE view) — Message Buffer 31 WORD1 Register
  fields as MB0_16B_WORD1
{0x880+4i} RXIMR[{i}] (i=0..31) reset not defined — Rx Individual Mask Registers
  [31:0] MI — Individual Mask Bits
0xB00 CTRL1_PN reset 0x100 — Pretended Networking Control 1 Register
  [17] WTOF_MSK — Wake Up by Timeout Flag Mask Bit
    0=DISABLE (Timeout wakeup event is disabled); 1=ENABLE (Timeout wakeup event is enabled)
  [16] WUMF_MSK — Wake Up by Match Flag Mask Bit
    0=DISABLE (Wakeup match event is disabled); 1=ENABLE (Wakeup match event is enabled)
  [15:8] NMATCH — Number of Messages Matching the Same Filtering Criteria
    1=match_1 (Received message must match the predefined filtering criteria for ID and/or PL once before generating a wakeup event.); 2=match_2 (Received message must match the predefined filtering criteria for ID and/or PL twice before generating a wakeup event.); 255=match_255 (Received message must match the predefined filtering criteria for ID and/or PL 255 times before generating a wakeup event.)
  [5:4] PLFS — Payload Filtering Selection
    0=match_exact (Match upon a payload contents against an exact target value); 1=match_GTE (Match upon a payload value greater than or equal to a specified target value); 2=match_LTE (Match upon a payload value smaller than or equal to a specified target value); 3=match_range (Match upon a payload value inside a range, greater than or equal to a specified lower limit, and smaller than or equal to a specified upper limit)
  [3:2] IDFS — ID Filtering Selection
    0=match_exact (Match upon ID contents against an exact target value); 1=match_GTE (Match upon an ID value greater than or equal to a specified target value); 2=match_LTE (Match upon an ID value smaller than or equal to a specified target value); 3=match_range (Match upon an ID value inside a range, greater than or equal to a specified lower limit, and smaller than or equal to a specified upper limit)
  [1:0] FCS — Filtering Combination Selection
    0=ID_filtering (Message ID filtering only); 1=ID_payload_filtering (Message ID filtering and payload filtering); 2=ID_filtering_number (Message ID filtering occurring a specified number of times); 3=ID_payload_filtering_number (Message ID filtering and payload filtering a specified number of times)
0xB04 CTRL2_PN — Pretended Networking Control 2 Register
  [15:0] MATCHTO — Timeout for No Message Matching the Filtering Criteria
0xB08 WU_MTC — Pretended Networking Wake Up Match Register
  [17] WTOF write-1-clears — Wake Up by Timeout Flag Bit
    0=No wakeup by timeout event detected; 1=Wakeup by timeout event detected
  [16] WUMF write-1-clears — Wake Up by Match Flag Bit
    0=no_match (No wakeup by match event detected); 1=match (Wakeup by match event detected)
  [15:8] MCOUNTER ro — Number of Matches when in Pretended Networking
0xB0C FLT_ID1 — Pretended Networking ID Filter 1 Register
  [30] FLT_IDE — ID Extended Filter
    0=standard (Accept standard frame format); 1=extended (Accept extended frame format)
  [29] FLT_RTR — Remote Transmission Request Filter
    0=Reject remote frame (accept data frame); 1=Accept remote frame
  [28:0] FLT_ID1 — ID Filter 1 for Pretended Networking filtering
0xB10 FLT_DLC reset 0x8 — Pretended Networking DLC Filter Register
  [19:16] FLT_DLC_LO — Lower Limit for Length of Data Bytes Filter
  [3:0] FLT_DLC_HI — Upper Limit for Length of Data Bytes Filter
0xB14 PL1_LO — Pretended Networking Payload Low Filter 1 Register
  [31-8n:24-8n] Data_byte_{n} (n=0..3) — Payload Filter 1 low order bits for Pretended Networking payload filtering corresponding to data byte {n}.
0xB18 PL1_HI — Pretended Networking Payload High Filter 1 Register
  [63-8n:56-8n] Data_byte_{n} (n=4..7) — Payload Filter 1 high order bits for Pretended Networking payload filtering corresponding to data byte {n}.
0xB1C FLT_ID2_IDMASK — Pretended Networking ID Filter 2 Register / ID Mask Register
  [30] IDE_MSK — ID Extended Mask Bit
    0=frame_format_no (The corresponding bit in the filter is "don't care"); 1=frame_format_yes (The corresponding bit in the filter is checked)
  [29] RTR_MSK — Remote Transmission Request Mask Bit
    0=frame_type_no (The corresponding bit in the filter is "don't care"); 1=frame_type_yes (The corresponding bit in the filter is checked)
  [28:0] FLT_ID2_IDMASK — ID Filter 2 for Pretended Networking Filtering / ID Mask Bits for Pretended Networking ID Filtering
0xB20 PL2_PLMASK_LO — Pretended Networking Payload Low Filter 2 Register / Payload Low Mask register
  [31-8n:24-8n] Data_byte_{n} (n=0..3) — Payload Filter 2 low order bits / Payload Mask low order bits for Pretended Networking payload filtering corresponding to the data byte {n}.
0xB24 PL2_PLMASK_HI — Pretended Networking Payload High Filter 2 low order bits / Payload High Mask register
  [63-8n:56-8n] Data_byte_{n} (n=4..7) — Payload Filter 2 high order bits / Payload Mask high order bits for Pretended Networking payload filtering corresponding to the data byte {n}.
{0xB40+0x10*i} WMB[{i}] (i=0..3) group
  0x00 WMB_CS ro — Wake Up Message Buffer register for C/S
    [22] SRR — Substitute Remote Request
    [21] IDE — ID Extended Bit
      0=standard (Frame format is standard); 1=extended (Frame format is extended)
    [20] RTR — Remote Transmission Request Bit
      0=not_remote (Frame is data one (not remote)); 1=remote (Frame is a remote one)
    [19:16] DLC — Length of Data in Bytes
  0x04 WMB_ID ro — Wake Up Message Buffer Register for ID
    [28:0] ID — Received ID under Pretended Networking mode
  0x08 WMB_D03 ro — Wake Up Message Buffer Register for Data 0-3
    [31-8n:24-8n] Data_byte_{n} (n=0..3) — Received payload corresponding to the data byte {n} under Pretended Networking mode
  0x0C WMB_D47 ro — Wake Up Message Buffer Register Data 4-7
    [63-8n:56-8n] Data_byte_{n} (n=4..7) — Received payload corresponding to the data byte {n} under Pretended Networking mode
0xBF0 EPRS — Enhanced CAN Bit Timing Prescalers
  [25:16] EDPRESDIV — Extended Data Phase Prescaler Division Factor
  [9:0] ENPRESDIV — Extended Nominal Prescaler Division Factor
0xBF4 ENCBT — Enhanced Nominal CAN Bit Timing
  [28:22] NRJW — Nominal Resynchronization Jump Width
  [18:12] NTSEG2 — Nominal Time Segment 2
  [7:0] NTSEG1 — Nominal Time Segment 1
0xBF8 EDCBT — Enhanced Data Phase CAN bit Timing
  [25:22] DRJW — Data Phase Resynchronization Jump Width
  [15:12] DTSEG2 — Data Phase Time Segment 2
  [4:0] DTSEG1 — Data Phase Segment 1
0xBFC ETDC — Enhanced Transceiver Delay Compensation
  [31] ETDCEN — Transceiver Delay Compensation Enable
    0=DISABLE (TDC is disabled); 1=ENABLE (TDC is enabled)
  [30] TDMDIS — Transceiver Delay Measurement Disable
    0=ENABLE (TDC measurement is enabled); 1=DISABLE (TDC measurement is disabled)
  [22:16] ETDCOFF — Enhanced Transceiver Delay Compensation Offset
  [15] ETDCFAIL write-1-clears — Transceiver Delay Compensation Fail
    0=in_range (Measured loop delay is in range.); 1=out_of_range (Measured loop delay is out of range.)
  [7:0] ETDCVAL ro — Enhanced Transceiver Delay Compensation Value
0xC00 FDCTRL reset 0x80000100 — CAN FD Control Register
  [31] FDRATE — Bit Rate Switch Enable
    0=nominal (Transmit a frame in nominal rate. The BRS bit in the Tx MB has no effect.); 1=bit_rate_switching (Transmit a frame with bit rate switching if the BRS bit in the Tx MB is recessive.)
  [17:16] MBDSR0 — Message Buffer Data Size for Region 0
    0=R0_8_bytes (Selects 8 bytes per message buffer.); 1=R0_16_bytes (Selects 16 bytes per message buffer.); 2=R0_32_bytes (Selects 32 bytes per message buffer.); 3=R0_64_bytes (Selects 64 bytes per message buffer.)
  [15] TDCEN — Transceiver Delay Compensation Enable
    0=DISABLE (TDC is disabled); 1=ENABLE (TDC is enabled)
  [14] TDCFAIL write-1-clears — Transceiver Delay Compensation Fail
    values as ETDC.ETDCFAIL
  [12:8] TDCOFF — Transceiver Delay Compensation Offset
  [5:0] TDCVAL ro — Transceiver Delay Compensation Value
0xC04 FDCBT — CAN FD Bit Timing Register
  [29:20] FPRESDIV — Fast Prescaler Division Factor
  [18:16] FRJW — Fast Resync Jump Width
  [14:10] FPROPSEG — Fast Propagation Segment
  [7:5] FPSEG1 — Fast Phase Segment 1
  [2:0] FPSEG2 — Fast Phase Segment 2
0xC08 FDCRC ro — CAN FD CRC Register
  [30:24] FD_MBCRC — CRC Mailbox Number for FD_TXCRC
  [20:0] FD_TXCRC — Extended Transmitted CRC value
0xC0C ERFCR — Enhanced Rx FIFO Control Register
  [31] ERFEN — Enhanced Rx FIFO enable
    0=DISABLE (Enhanced Rx FIFO is disabled); 1=ENABLE (Enhanced Rx FIFO is enabled)
  [30:26] DMALW — DMA Last Word
  [22:16] NEXIF — Number of Extended ID Filter Elements
  [13:8] NFE — Number of Enhanced Rx FIFO Filter Elements
  [4:0] ERFWM — Enhanced Rx FIFO Watermark
0xC10 ERFIER — Enhanced Rx FIFO Interrupt Enable Register
  [31] ERFUFWIE — Enhanced Rx FIFO Underflow Interrupt Enable
    0=DISABLE (Enhanced Rx FIFO Underflow interrupt is disabled); 1=ENABLE (Enhanced Rx FIFO Underflow interrupt is enabled)
  [30] ERFOVFIE — Enhanced Rx FIFO Overflow Interrupt Enable
    0=DISABLE (Enhanced Rx FIFO Overflow is disabled); 1=ENABLE (Enhanced Rx FIFO Overflow is enabled)
  [29] ERFWMIIE — Enhanced Rx FIFO Watermark Indication Interrupt Enable
    0=DISABLE (Enhanced Rx FIFO Watermark interrupt is disabled); 1=ENABLE (Enhanced Rx FIFO Watermark interrupt is enabled)
  [28] ERFDAIE — Enhanced Rx FIFO Data Available Interrupt Enable
    0=DISABLE (Enhanced Rx FIFO Data Available interrupt is disabled); 1=ENABLE (Enhanced Rx FIFO Data Available interrupt is enabled)
0xC14 ERFSR — Enhanced Rx FIFO Status Register
  [31] ERFUFW write-1-clears — Enhanced Rx FIFO Underflow
    0=no_underflow (No such occurrence); 1=underflow (Enhanced Rx FIFO underflow)
  [30] ERFOVF write-1-clears — Enhanced Rx FIFO Overflow
    0=no_overflow (No such occurrence); 1=overflow (Enhanced Rx FIFO overflow)
  [29] ERFWMI write-1-clears — Enhanced Rx FIFO Watermark Indication
    0=watermark_no (No such occurrence); 1=watermark_yes (The number of messages in FIFO is greater than the watermark)
  [28] ERFDA write-1-clears — Enhanced Rx FIFO Data Available
    0=no_message_stored (No such occurrence); 1=message_stored (There is at least one message stored in Enhanced Rx FIFO)
  [27] ERFCLR — Enhanced Rx FIFO Clear
    0=no_effect; 1=Clear Enhanced Rx FIFO content
  [17] ERFE ro — Enhanced Rx FIFO empty
    0=not_empty (Enhanced Rx FIFO is not empty); 1=empty (Enhanced Rx FIFO is empty)
  [16] ERFF ro — Enhanced Rx FIFO full
    0=not_full (Enhanced Rx FIFO is not full); 1=full (Enhanced Rx FIFO is full)
  [5:0] ERFEL ro — Enhanced Rx FIFO Elements
{0x3000+4i} ERFFEL[{i}] (i=0..31) reset not defined — Enhanced Rx FIFO Filter Element
  [31:0] FEL — Filter Element Bits
